# crc_reva register map
Registers are read-write, no defined reset value unless marked. A register's access mark holds for its fields unless they carry their own. Offsets are from the block's base; lines under a group give offsets from that group; [hi:lo] are bit positions; {n}, {i} and the like mark numbered series; 'fields as' and 'values as' point back to an identical list; <NAME> marks a mode.

## Memory map
0x4000F000 CRC size 0x1000 — CRC Registers.

## CRC — CRC Registers.
Base 0x4000F000
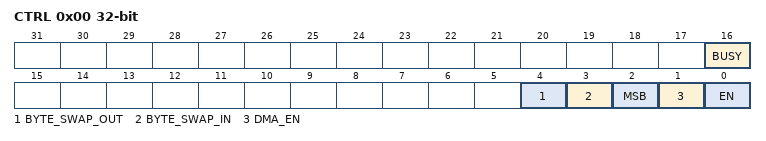
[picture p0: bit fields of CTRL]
0x00 CTRL 32-bit — CRC Control
  [16] BUSY — CRC Busy
  [4] BYTE_SWAP_OUT — Byte Swap CRC Value Output
  [3] BYTE_SWAP_IN — Byte Swap CRC Data Input
  [2] MSB — MSB Select
  [1] DMA_EN — DMA Request Enable
  [0] EN — CRC Enable
0x04 DATAIN32 — CRC Data Input
  [31:0] DATA — CRC Data
{0x4+2i} DATAIN16[{i}] (i=0..1) 16-bit — CRC Data Input
  [15:0] DATA — CRC Data
{0x4+4i} DATAIN8[{i}] (i=0..3) 8-bit — CRC Data Input
  [7:0] DATA — CRC Data
0x08 POLY — CRC Polynomial
  [31:0] POLY
0x0C VAL — Current CRC Value
  [31:0] VALUE
